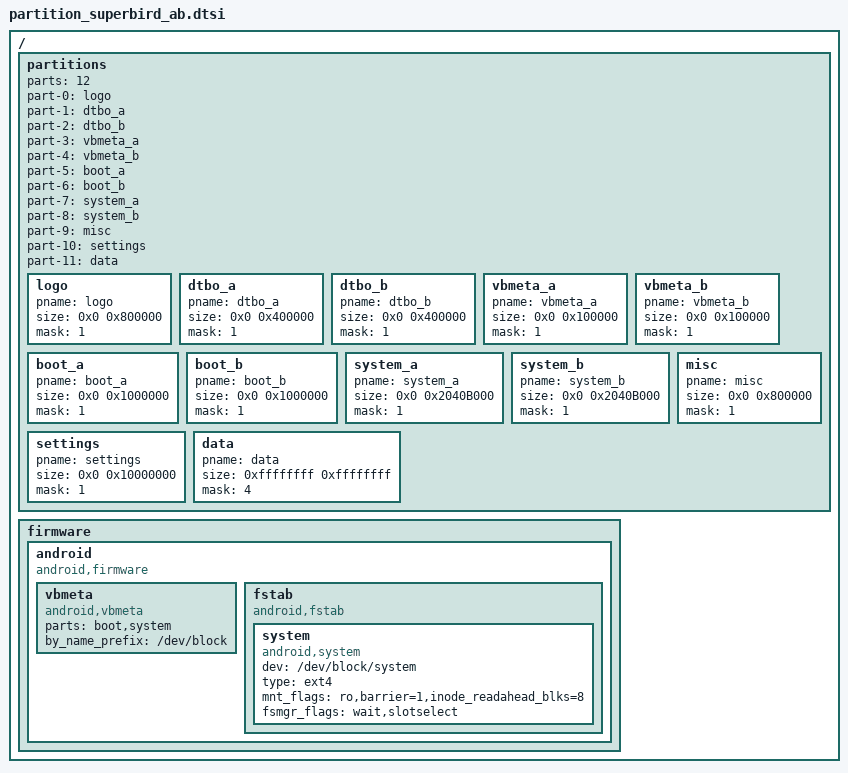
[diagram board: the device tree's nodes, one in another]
/*
 * Amlogic partition set for normal
 *
 * Copyright (c) 2017-2017 Amlogic Ltd
 *
 * This file is licensed under a dual GPLv2 or BSD license.
 * 
 * logo = boot logo 
 * tee = trusted execution environment (Android)
 * 
 */
/ {
	partitions: partitions{
		parts = <12>;
		part-0 = <&logo>;
		part-1 = <&dtbo_a>;
		part-2 = <&dtbo_b>;
		part-3 = <&vbmeta_a>;
		part-4 = <&vbmeta_b>;
		part-5 = <&boot_a>;
		part-6 = <&boot_b>;
		part-7 = <&system_a>;
		part-8 = <&system_b>;
		part-9 = <&misc>;
		part-10 = <&settings>;
		part-11 = <&data>;

		logo:logo{
			pname = "logo";
			size = <0x0 0x800000>;
			mask = <1>;
		};
		dtbo_a:dtbo_a{
			pname = "dtbo_a";
			size = <0x0 0x400000>;
			mask = <1>;
		};
		dtbo_b:dtbo_b{
			pname = "dtbo_b";
			size = <0x0 0x400000>;
			mask = <1>;
		};
		vbmeta_a:vbmeta_a{
			pname = "vbmeta_a";
			size = <0x0 0x100000>;
			mask = <1>;
		};
		vbmeta_b:vbmeta_b{
			pname = "vbmeta_b";
			size = <0x0 0x100000>;
			mask = <1>;
		};
		boot_a:boot_a{
			pname = "boot_a";
			size = <0x0 0x1000000>;
			mask = <1>;
		};
		boot_b:boot_b{
			pname = "boot_b";
			size = <0x0 0x1000000>;
			mask = <1>;
		};
		system_a:system_a{
			pname = "system_a";
			size = <0x0 0x2040B000>;
			mask = <1>;
		};
		system_b:system_b{
			pname = "system_b";
			size = <0x0 0x2040B000>;
			mask = <1>;
		};
		misc:misc{
			pname = "misc";
			size = <0x0 0x800000>;
			mask = <1>;
		};
		settings:settings{
			pname = "settings";
			size = <0x0 0x10000000>;
			mask = <1>;
		};
		data:data{
			pname = "data";
			size = <0xffffffff 0xffffffff>;
			mask = <4>;
		};
	};

	firmware {
		android {
			compatible = "android,firmware";
			vbmeta {
				compatible = "android,vbmeta";
				parts = "boot,system";
				by_name_prefix="/dev/block";
			};
		fstab {
			compatible = "android,fstab";
			system {
				compatible = "android,system";
				dev = "/dev/block/system";
				type = "ext4";
				mnt_flags = "ro,barrier=1,inode_readahead_blks=8";
				fsmgr_flags = "wait,slotselect";
				};
			};
		};
	};

};/* end of / */
